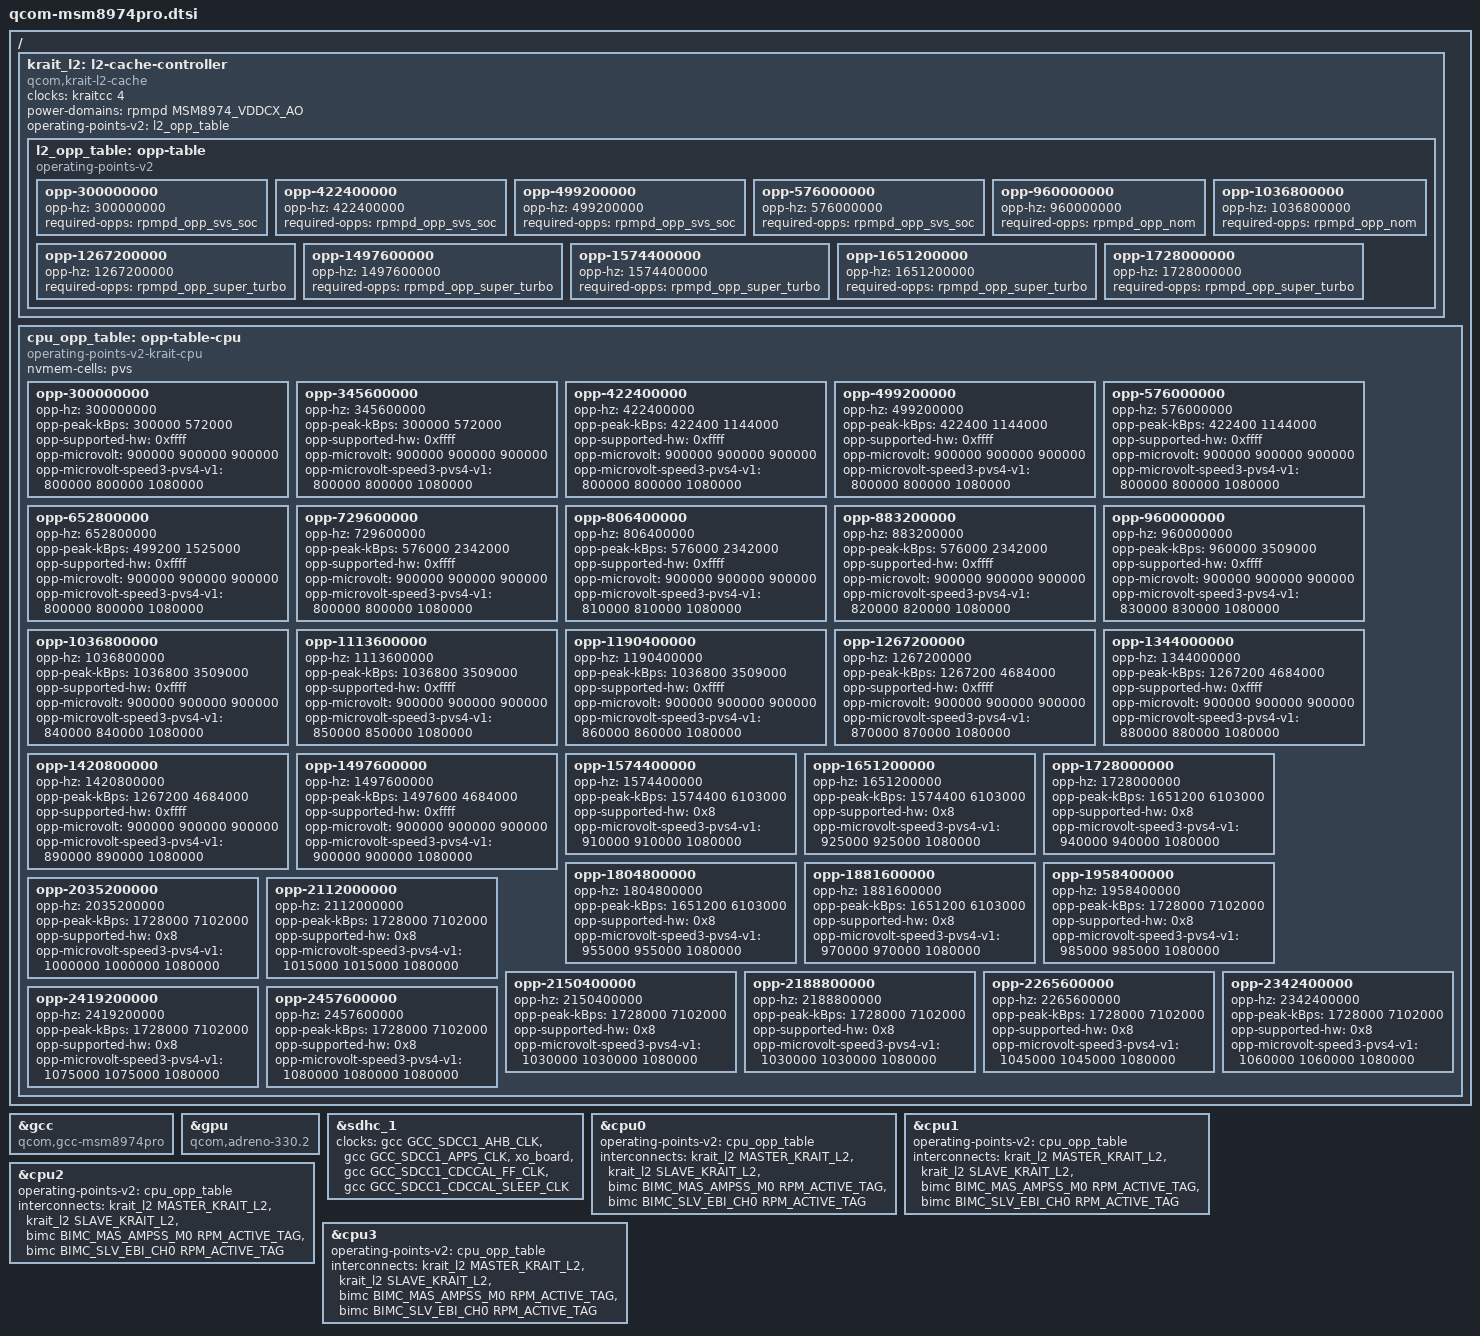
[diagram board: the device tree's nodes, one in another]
// SPDX-License-Identifier: GPL-2.0
#include <dt-bindings/soc/qcom,krait-l2-cache.h>

#include "qcom-msm8974.dtsi"

&gcc {
	compatible = "qcom,gcc-msm8974pro";
};

&gpu {
	compatible = "qcom,adreno-330.2", "qcom,adreno";
};

&sdhc_1 {
	clocks = <&gcc GCC_SDCC1_AHB_CLK>,
		 <&gcc GCC_SDCC1_APPS_CLK>,
		 <&xo_board>,
		 <&gcc GCC_SDCC1_CDCCAL_FF_CLK>,
		 <&gcc GCC_SDCC1_CDCCAL_SLEEP_CLK>;
	clock-names = "iface", "core", "xo", "cal", "sleep";
};

/ {
	krait_l2: l2-cache-controller {
		compatible = "qcom,krait-l2-cache";
		clocks = <&kraitcc 4>;
		power-domains = <&rpmpd MSM8974_VDDCX_AO>;
		operating-points-v2 = <&l2_opp_table>;
		#interconnect-cells = <1>;

		l2_opp_table: opp-table {
			compatible = "operating-points-v2";

			opp-300000000 {
				opp-hz = /bits/ 64 <300000000>;
				required-opps = <&rpmpd_opp_svs_soc>;
			};

			opp-422400000 {
				opp-hz = /bits/ 64 <422400000>;
				required-opps = <&rpmpd_opp_svs_soc>;
			};

			opp-499200000 {
				opp-hz = /bits/ 64 <499200000>;
				required-opps = <&rpmpd_opp_svs_soc>;
			};

			opp-576000000 {
				opp-hz = /bits/ 64 <576000000>;
				required-opps = <&rpmpd_opp_svs_soc>;
			};

			opp-960000000 {
				opp-hz = /bits/ 64 <960000000>;
				required-opps = <&rpmpd_opp_nom>;
			};

			opp-1036800000 {
				opp-hz = /bits/ 64 <1036800000>;
				required-opps = <&rpmpd_opp_nom>;
			};

			opp-1267200000 {
				opp-hz = /bits/ 64 <1267200000>;
				required-opps = <&rpmpd_opp_super_turbo>;
			};

			opp-1497600000 {
				opp-hz = /bits/ 64 <1497600000>;
				required-opps = <&rpmpd_opp_super_turbo>;
			};

			opp-1574400000 {
				opp-hz = /bits/ 64 <1574400000>;
				required-opps = <&rpmpd_opp_super_turbo>;
			};

			opp-1651200000 {
				opp-hz = /bits/ 64 <1651200000>;
				required-opps = <&rpmpd_opp_super_turbo>;
			};

			opp-1728000000 {
				opp-hz = /bits/ 64 <1728000000>;
				required-opps = <&rpmpd_opp_super_turbo>;
			};
		};
	};

	cpu_opp_table: opp-table-cpu {
		compatible = "operating-points-v2-krait-cpu";
		nvmem-cells = <&pvs>;

		opp-300000000 {
			opp-hz = /bits/ 64 <300000000>;
			opp-peak-kBps = <300000 572000>;
			opp-supported-hw = <0xffff>;
			opp-microvolt = <900000 900000 900000>;
			opp-microvolt-speed3-pvs4-v1 = <800000 800000 1080000>;
		};

		opp-345600000 {
			opp-hz = /bits/ 64 <345600000>;
			opp-peak-kBps = <300000 572000>;
			opp-supported-hw = <0xffff>;
			opp-microvolt = <900000 900000 900000>;
			opp-microvolt-speed3-pvs4-v1 = <800000 800000 1080000>;
		};

		opp-422400000 {
			opp-hz = /bits/ 64 <422400000>;
			opp-peak-kBps = <422400 1144000>;
			opp-supported-hw = <0xffff>;
			opp-microvolt = <900000 900000 900000>;
			opp-microvolt-speed3-pvs4-v1 = <800000 800000 1080000>;
		};

		opp-499200000 {
			opp-hz = /bits/ 64 <499200000>;
			opp-peak-kBps = <422400 1144000>;
			opp-supported-hw = <0xffff>;
			opp-microvolt = <900000 900000 900000>;
			opp-microvolt-speed3-pvs4-v1 = <800000 800000 1080000>;
		};

		opp-576000000 {
			opp-hz = /bits/ 64 <576000000>;
			opp-peak-kBps = <422400 1144000>;
			opp-supported-hw = <0xffff>;
			opp-microvolt = <900000 900000 900000>;
			opp-microvolt-speed3-pvs4-v1 = <800000 800000 1080000>;
		};

		opp-652800000 {
			opp-hz = /bits/ 64 <652800000>;
			opp-peak-kBps = <499200 1525000>;
			opp-supported-hw = <0xffff>;
			opp-microvolt = <900000 900000 900000>;
			opp-microvolt-speed3-pvs4-v1 = <800000 800000 1080000>;
		};

		opp-729600000 {
			opp-hz = /bits/ 64 <729600000>;
			opp-peak-kBps = <576000 2342000>;
			opp-supported-hw = <0xffff>;
			opp-microvolt = <900000 900000 900000>;
			opp-microvolt-speed3-pvs4-v1 = <800000 800000 1080000>;
		};

		opp-806400000 {
			opp-hz = /bits/ 64 <806400000>;
			opp-peak-kBps = <576000 2342000>;
			opp-supported-hw = <0xffff>;
			opp-microvolt = <900000 900000 900000>;
			opp-microvolt-speed3-pvs4-v1 = <810000 810000 1080000>;
		};

		opp-883200000 {
			opp-hz = /bits/ 64 <883200000>;
			opp-peak-kBps = <576000 2342000>;
			opp-supported-hw = <0xffff>;
			opp-microvolt = <900000 900000 900000>;
			opp-microvolt-speed3-pvs4-v1 = <820000 820000 1080000>;
		};

		opp-960000000 {
			opp-hz = /bits/ 64 <960000000>;
			opp-peak-kBps = <960000 3509000>;
			opp-supported-hw = <0xffff>;
			opp-microvolt = <900000 900000 900000>;
			opp-microvolt-speed3-pvs4-v1 = <830000 830000 1080000>;
		};

		opp-1036800000 {
			opp-hz = /bits/ 64 <1036800000>;
			opp-peak-kBps = <1036800 3509000>;
			opp-supported-hw = <0xffff>;
			opp-microvolt = <900000 900000 900000>;
			opp-microvolt-speed3-pvs4-v1 = <840000 840000 1080000>;
		};

		opp-1113600000 {
			opp-hz = /bits/ 64 <1113600000>;
			opp-peak-kBps = <1036800 3509000>;
			opp-supported-hw = <0xffff>;
			opp-microvolt = <900000 900000 900000>;
			opp-microvolt-speed3-pvs4-v1 = <850000 850000 1080000>;
		};

		opp-1190400000 {
			opp-hz = /bits/ 64 <1190400000>;
			opp-peak-kBps = <1036800 3509000>;
			opp-supported-hw = <0xffff>;
			opp-microvolt = <900000 900000 900000>;
			opp-microvolt-speed3-pvs4-v1 = <860000 860000 1080000>;
		};

		opp-1267200000 {
			opp-hz = /bits/ 64 <1267200000>;
			opp-peak-kBps = <1267200 4684000>;
			opp-supported-hw = <0xffff>;
			opp-microvolt = <900000 900000 900000>;
			opp-microvolt-speed3-pvs4-v1 = <870000 870000 1080000>;
		};

		opp-1344000000 {
			opp-hz = /bits/ 64 <1344000000>;
			opp-peak-kBps = <1267200 4684000>;
			opp-supported-hw = <0xffff>;
			opp-microvolt = <900000 900000 900000>;
			opp-microvolt-speed3-pvs4-v1 = <880000 880000 1080000>;
		};

		opp-1420800000 {
			opp-hz = /bits/ 64 <1420800000>;
			opp-peak-kBps = <1267200 4684000>;
			opp-supported-hw = <0xffff>;
			opp-microvolt = <900000 900000 900000>;
			opp-microvolt-speed3-pvs4-v1 = <890000 890000 1080000>;
		};

		opp-1497600000 {
			opp-hz = /bits/ 64 <1497600000>;
			opp-peak-kBps = <1497600 4684000>;
			opp-supported-hw = <0xffff>;
			opp-microvolt = <900000 900000 900000>;
			opp-microvolt-speed3-pvs4-v1 = <900000 900000 1080000>;
		};

		opp-1574400000 {
			opp-hz = /bits/ 64 <1574400000>;
			opp-peak-kBps = <1574400 6103000>;
			opp-supported-hw = <0x8>;
			opp-microvolt-speed3-pvs4-v1 = <910000 910000 1080000>;
		};

		opp-1651200000 {
			opp-hz = /bits/ 64 <1651200000>;
			opp-peak-kBps = <1574400 6103000>;
			opp-supported-hw = <0x8>;
			opp-microvolt-speed3-pvs4-v1 = <925000 925000 1080000>;
		};

		opp-1728000000 {
			opp-hz = /bits/ 64 <1728000000>;
			opp-peak-kBps = <1651200 6103000>;
			opp-supported-hw = <0x8>;
			opp-microvolt-speed3-pvs4-v1 = <940000 940000 1080000>;
		};

		opp-1804800000 {
			opp-hz = /bits/ 64 <1804800000>;
			opp-peak-kBps = <1651200 6103000>;
			opp-supported-hw = <0x8>;
			opp-microvolt-speed3-pvs4-v1 = <955000 955000 1080000>;
		};

		opp-1881600000 {
			opp-hz = /bits/ 64 <1881600000>;
			opp-peak-kBps = <1651200 6103000>;
			opp-supported-hw = <0x8>;
			opp-microvolt-speed3-pvs4-v1 = <970000 970000 1080000>;
		};

		opp-1958400000 {
			opp-hz = /bits/ 64 <1958400000>;
			opp-peak-kBps = <1728000 7102000>;
			opp-supported-hw = <0x8>;
			opp-microvolt-speed3-pvs4-v1 = <985000 985000 1080000>;
		};

		opp-2035200000 {
			opp-hz = /bits/ 64 <2035200000>;
			opp-peak-kBps = <1728000 7102000>;
			opp-supported-hw = <0x8>;
			opp-microvolt-speed3-pvs4-v1 = <1000000 1000000 1080000>;
		};

		opp-2112000000 {
			opp-hz = /bits/ 64 <2112000000>;
			opp-peak-kBps = <1728000 7102000>;
			opp-supported-hw = <0x8>;
			opp-microvolt-speed3-pvs4-v1 = <1015000 1015000 1080000>;
		};

		opp-2150400000 {
			opp-hz = /bits/ 64 <2150400000>;
			opp-peak-kBps = <1728000 7102000>;
			opp-supported-hw = <0x8>;
			opp-microvolt-speed3-pvs4-v1 = <1030000 1030000 1080000>;
		};

		opp-2188800000 {
			opp-hz = /bits/ 64 <2188800000>;
			opp-peak-kBps = <1728000 7102000>;
			opp-supported-hw = <0x8>;
			opp-microvolt-speed3-pvs4-v1 = <1030000 1030000 1080000>;
		};

		opp-2265600000 {
			opp-hz = /bits/ 64 <2265600000>;
			opp-peak-kBps = <1728000 7102000>;
			opp-supported-hw = <0x8>;
			opp-microvolt-speed3-pvs4-v1 = <1045000 1045000 1080000>;
		};

		opp-2342400000 {
			opp-hz = /bits/ 64 <2342400000>;
			opp-peak-kBps = <1728000 7102000>;
			opp-supported-hw = <0x8>;
			opp-microvolt-speed3-pvs4-v1 = <1060000 1060000 1080000>;
		};

		opp-2419200000 {
			opp-hz = /bits/ 64 <2419200000>;
			opp-peak-kBps = <1728000 7102000>;
			opp-supported-hw = <0x8>;
			opp-microvolt-speed3-pvs4-v1 = <1075000 1075000 1080000>;
		};

		opp-2457600000 {
			opp-hz = /bits/ 64 <2457600000>;
			opp-peak-kBps = <1728000 7102000>;
			opp-supported-hw = <0x8>;
			opp-microvolt-speed3-pvs4-v1 = <1080000 1080000 1080000>;
		};
	};
};

&cpu0 {
	operating-points-v2 = <&cpu_opp_table>;
	interconnects = <&krait_l2 MASTER_KRAIT_L2 &krait_l2 SLAVE_KRAIT_L2>,
			<&bimc BIMC_MAS_AMPSS_M0 RPM_ACTIVE_TAG &bimc BIMC_SLV_EBI_CH0 RPM_ACTIVE_TAG>;
};

&cpu1 {
	operating-points-v2 = <&cpu_opp_table>;
	interconnects = <&krait_l2 MASTER_KRAIT_L2 &krait_l2 SLAVE_KRAIT_L2>,
			<&bimc BIMC_MAS_AMPSS_M0 RPM_ACTIVE_TAG &bimc BIMC_SLV_EBI_CH0 RPM_ACTIVE_TAG>;
};

&cpu2 {
	operating-points-v2 = <&cpu_opp_table>;
	interconnects = <&krait_l2 MASTER_KRAIT_L2 &krait_l2 SLAVE_KRAIT_L2>,
			<&bimc BIMC_MAS_AMPSS_M0 RPM_ACTIVE_TAG &bimc BIMC_SLV_EBI_CH0 RPM_ACTIVE_TAG>;
};

&cpu3 {
	operating-points-v2 = <&cpu_opp_table>;
	interconnects = <&krait_l2 MASTER_KRAIT_L2 &krait_l2 SLAVE_KRAIT_L2>,
			<&bimc BIMC_MAS_AMPSS_M0 RPM_ACTIVE_TAG &bimc BIMC_SLV_EBI_CH0 RPM_ACTIVE_TAG>;
};
